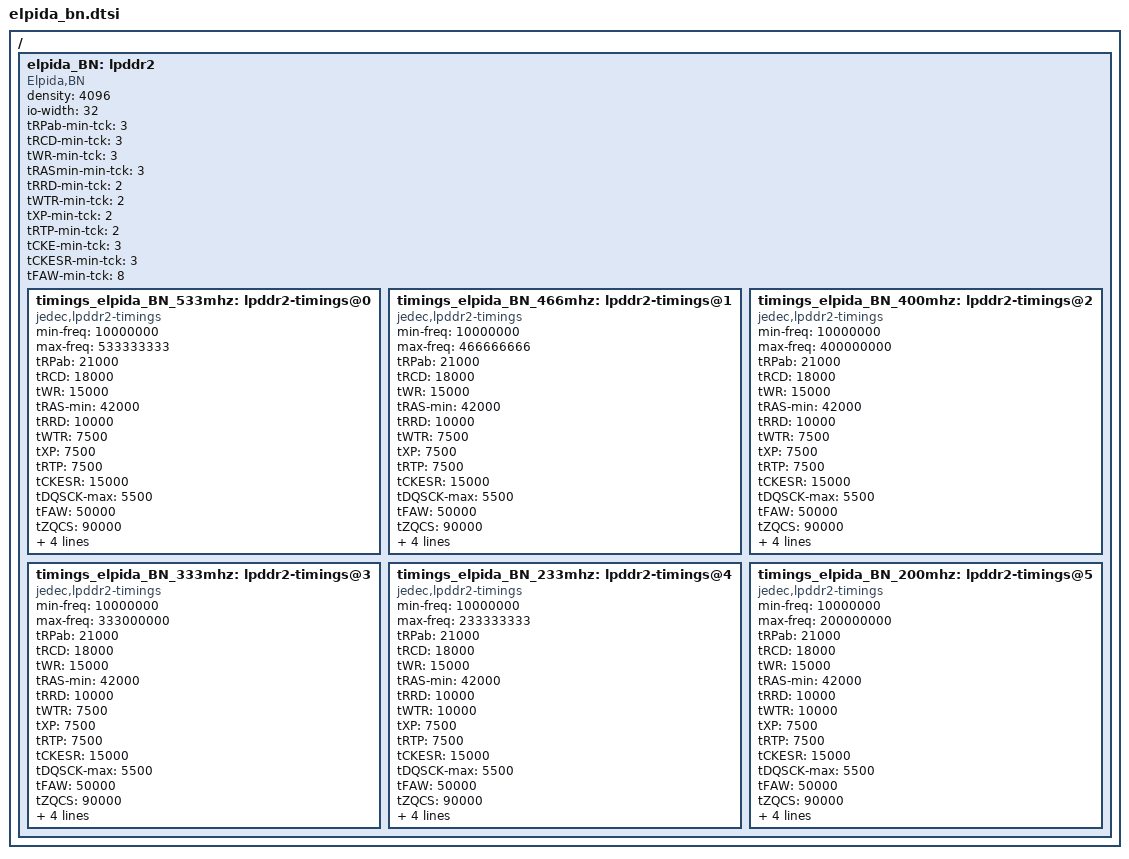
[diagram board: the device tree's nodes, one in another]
/*
 * Common devices used in different OMAP boards
 */

/ {
	elpida_BN: lpddr2 {
		compatible	= "Elpida,BN","jedec,lpddr2-s4";
		density		= <4096>;
		io-width	= <32>;

		tRPab-min-tck	= <3>;
		tRCD-min-tck	= <3>;
		tWR-min-tck	= <3>;
		tRASmin-min-tck	= <3>;
		tRRD-min-tck	= <2>;
		tWTR-min-tck	= <2>;
		tXP-min-tck	= <2>;
		tRTP-min-tck	= <2>;
		tCKE-min-tck	= <3>;
		tCKESR-min-tck	= <3>;
		tFAW-min-tck	= <8>;

		timings_elpida_BN_533mhz: lpddr2-timings@0 {
			compatible	= "jedec,lpddr2-timings";
			min-freq	= <10000000>;
			max-freq	= <533333333>;
			tRPab		= <21000>;
			tRCD		= <18000>;
			tWR		= <15000>;
			tRAS-min	= <42000>;
			tRRD		= <10000>;
			tWTR		= <7500>;
			tXP		= <7500>;
			tRTP		= <7500>;
			tCKESR		= <15000>;
			tDQSCK-max	= <5500>;
			tFAW		= <50000>;
			tZQCS		= <90000>;
			tZQCL		= <360000>;
			tZQinit		= <1000000>;
			tRAS-max-ns	= <70000>;
			tDQSCK-max-derated = <5620>;
		};

		timings_elpida_BN_466mhz: lpddr2-timings@1 {
			compatible	= "jedec,lpddr2-timings";
			min-freq	= <10000000>;
			max-freq	= <466666666>;
			tRPab		= <21000>;
			tRCD		= <18000>;
			tWR		= <15000>;
			tRAS-min	= <42000>;
			tRRD		= <10000>;
			tWTR		= <7500>;
			tXP		= <7500>;
			tRTP		= <7500>;
			tCKESR		= <15000>;
			tDQSCK-max	= <5500>;
			tFAW		= <50000>;
			tZQCS		= <90000>;
			tZQCL		= <360000>;
			tZQinit		= <1000000>;
			tRAS-max-ns	= <70000>;
			tDQSCK-max-derated = <6000>;
		};

		timings_elpida_BN_400mhz: lpddr2-timings@2 {
			compatible	= "jedec,lpddr2-timings";
			min-freq	= <10000000>;
			max-freq	= <400000000>;
			tRPab		= <21000>;
			tRCD		= <18000>;
			tWR		= <15000>;
			tRAS-min	= <42000>;
			tRRD		= <10000>;
			tWTR		= <7500>;
			tXP		= <7500>;
			tRTP		= <7500>;
			tCKESR		= <15000>;
			tDQSCK-max	= <5500>;
			tFAW		= <50000>;
			tZQCS		= <90000>;
			tZQCL		= <360000>;
			tZQinit		= <1000000>;
			tRAS-max-ns	= <70000>;
			tDQSCK-max-derated = <6000>;
		};

		timings_elpida_BN_333mhz: lpddr2-timings@3 {
			compatible	= "jedec,lpddr2-timings";
			min-freq	= <10000000>;
			max-freq	= <333000000>;
			tRPab		= <21000>;
			tRCD		= <18000>;
			tWR		= <15000>;
			tRAS-min	= <42000>;
			tRRD		= <10000>;
			tWTR		= <7500>;
			tXP		= <7500>;
			tRTP		= <7500>;
			tCKESR		= <15000>;
			tDQSCK-max	= <5500>;
			tFAW		= <50000>;
			tZQCS		= <90000>;
			tZQCL		= <360000>;
			tZQinit		= <1000000>;
			tRAS-max-ns	= <70000>;
			tDQSCK-max-derated = <6000>;
		};

		timings_elpida_BN_233mhz: lpddr2-timings@4 {
			compatible	= "jedec,lpddr2-timings";
			min-freq	= <10000000>;
			max-freq	= <233333333>;
			tRPab		= <21000>;
			tRCD		= <18000>;
			tWR		= <15000>;
			tRAS-min	= <42000>;
			tRRD		= <10000>;
			tWTR		= <10000>;
			tXP		= <7500>;
			tRTP		= <7500>;
			tCKESR		= <15000>;
			tDQSCK-max	= <5500>;
			tFAW		= <50000>;
			tZQCS		= <90000>;
			tZQCL		= <360000>;
			tZQinit		= <1000000>;
			tRAS-max-ns	= <70000>;
			tDQSCK-max-derated = <6000>;
		};

		timings_elpida_BN_200mhz: lpddr2-timings@5 {
			compatible	= "jedec,lpddr2-timings";
			min-freq	= <10000000>;
			max-freq	= <200000000>;
			tRPab		= <21000>;
			tRCD		= <18000>;
			tWR		= <15000>;
			tRAS-min	= <42000>;
			tRRD		= <10000>;
			tWTR		= <10000>;
			tXP		= <7500>;
			tRTP		= <7500>;
			tCKESR		= <15000>;
			tDQSCK-max	= <5500>;
			tFAW		= <50000>;
			tZQCS		= <90000>;
			tZQCL		= <360000>;
			tZQinit		= <1000000>;
			tRAS-max-ns	= <70000>;
			tDQSCK-max-derated = <6000>;
		};
	};
};
